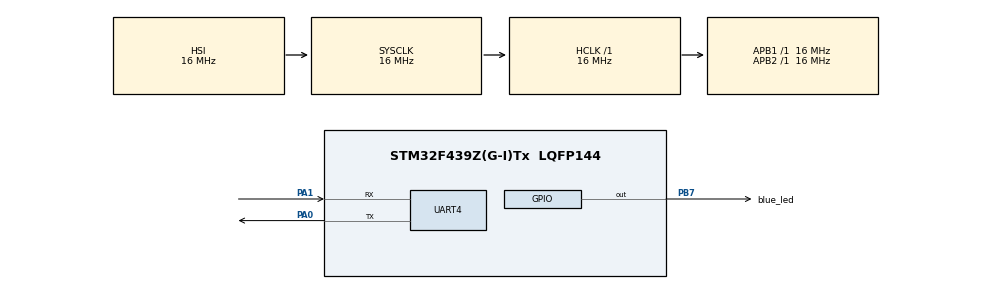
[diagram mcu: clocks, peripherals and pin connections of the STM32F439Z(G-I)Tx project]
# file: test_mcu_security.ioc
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Mcu.Family=STM32F4
Mcu.Name=STM32F439Z(G-I)Tx
Mcu.Package=LQFP144
NVIC.PriorityGroup=NVIC_PRIORITYGROUP_4
PA0/WKUP.Mode=Asynchronous
PA0/WKUP.Signal=UART4_TX
PA1.Mode=Asynchronous
PA1.Signal=UART4_RX
PB7.GPIO_Label=blue_led
PB7.Signal=GPIO_Output
ProjectManager.HeapSize=0x200
ProjectManager.StackSize=0x400
ProjectManager.TargetToolchain=STM32CubeIDE
RCC.AHBFreq_Value=16000000
RCC.APB1Freq_Value=16000000
RCC.APB2Freq_Value=16000000
RCC.CortexFreq_Value=16000000
RCC.HSE_VALUE=25000000
RCC.HSI_VALUE=16000000
RCC.LSE_VALUE=32768
RCC.SYSCLKFreq_VALUE=16000000
RCC.VCOOutputFreq_Value=192000000
UART4.VirtualMode=Asynchronous
VP_RNG_VS_RNG.Mode=RNG_Activate
VP_wolfSSL.I-CUBE-wolfSSL_VS_wolfSSLJjwolfSSL_5.5.4_5.5.4.Mode=wolfSSLJjwolfSSL
board=custom
wolfSSL.I-CUBE-wolfSSL.5.5.4.WOLF_CONF_AESGCM=0
wolfSSL.I-CUBE-wolfSSL.5.5.4.WOLF_CONF_DH=0
wolfSSL.I-CUBE-wolfSSL.5.5.4.WOLF_CONF_ECC=1
wolfSSL.I-CUBE-wolfSSL.5.5.4.WOLF_CONF_OPENSSL_EXTRA=2
wolfSSL.I-CUBE-wolfSSL.5.5.4.WOLF_CONF_TEST=0
wolfSSL.I-CUBE-wolfSSL.5.5.4.WOLF_CONF_TLS12=0
wolfSSL.I-CUBE-wolfSSL.5.5.4.wolfSSLCcwolfSSLJjwolfCryptJjCore=true
wolfSSL.I-CUBE-wolfSSL.5.5.4.wolfSSLCcwolfSSLJjwolfSSLJjCore=true

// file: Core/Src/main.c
/* USER CODE BEGIN Header */
/**
 ******************************************************************************
 * @file           : main.c
 * @brief          : Main program body
 ******************************************************************************
 * @attention
 *
 * Copyright (c) 2023 STMicroelectronics.
 * All rights reserved.
 *
 * This software is licensed under terms that can be found in the LICENSE file
 * in the root directory of this software component.
 * If no LICENSE file comes with this software, it is provided AS-IS.
 *
 ******************************************************************************
 */
/* USER CODE END Header */
#include "main.h"

/* USER CODE BEGIN Includes */
#include "stdio.h"
#include "wolfssl/wolfcrypt/signature.h"
#include "wolfssl/wolfcrypt/rsa.h"
#include "wolfssl/ssl.h"
/* USER CODE END Includes */

/* USER CODE BEGIN PM */
#define APPLICATION_EXENSIONS_ADDRESS    0x08040000

#define ROOT_CERT_ADDRESS 				 APPLICATION_EXENSIONS_ADDRESS
#define SB_CERT_ADDRESS 			    (APPLICATION_EXENSIONS_ADDRESS + 0x0800)    //0x08040800 //2K byte offset from Application_extensions_Address
#define META_DATA_ADDRESS               (APPLICATION_EXENSIONS_ADDRESS + 0x01000)   //0x08041000 //4k byte offset from Application_extensions_Address
#define SIGNATURE_ADDRESS               (APPLICATION_EXENSIONS_ADDRESS + 0x01400)	//0x08041400 //5k byte offset from Application_extensions_Address
#define CERTIFICATES_METADATA_ADDRESS   (APPLICATION_EXENSIONS_ADDRESS + 0x01600)   //0x08041600

#define MAIN_APPLICATION_START_ADDRESS  (0x08060000U)   //6k byte offset from Application_extensions_Address

#define ROOT_1_REVOCATION_ADDRESS  (0x1fff7800) //first byte in the Block 0 - OTP
#define ROOT_2_REVOCATION_ADDRESS  (0x1fff7820) //first byte in the Block 1 - OTP

#define META_DATA_LENGTH 82

#define MAJOR_V_METADATA_OFFSET         8
#define MINOR_V_METADATA_OFFSET         10
#define PATCH_V_METADATA_OFFSET         12
#define APP_SIZE__METADATA_OFFSET       20
#define ROOT_INDEX__METADATA_OFFSET     38
#define APP_HASH__METADATA_OFFSET       50

#define ROOT_CERT_SIZE_C_METADATA_OFFSET  15
#define SB_CERT_SIZE_C_METADATA_OFFSET    34
/* USER CODE END PM */

RNG_HandleTypeDef hrng;

/* USER CODE BEGIN PV */

int sigLen = 256;
byte *sigBuf =(byte *)SIGNATURE_ADDRESS;
byte *Meta_Data=(byte *)META_DATA_ADDRESS;

long expected_n_root_chain_1_public_key[] = {
		    0xa204ba2d ,0x3d6db507 ,0x4cf9130c ,0x7a2696bb ,0x3b95941b ,0x60c4c14b ,0xb9db3d47 ,
		   	0x96c5d01e ,0x4c294e55 ,0xe9fbe300 ,0x1cd028c5 ,0x8d2387e9 ,0xc1a80302 ,0x5f12af64 ,
			0x7708d0b9 ,0x9714e69d ,0xf94449d4 ,0xad00fd72 ,0xd56f1391 ,0xfb439ee5 ,0xbf35a512 ,
		   	0xda25deeb ,0xdea24a14 ,0xec3d81a2 ,0x5d44de9e ,0xfcad0f71 ,0xaabef73d ,0x63b95934 ,
		   	0xe5438b15 ,0xc92bcd84 ,0x4b7bd6b6 ,0x96080734 ,0x9e5a9a96 ,0xa30cebb2 ,0x5bf80843 ,
		   	0x69800465 ,0x135bc1db ,0x584a8dd  ,0x85a63d2c ,0x213f1976 ,0x1a5f03aa ,0xa346e215 ,
		   	0x75e22fd9 ,0x761ed052 ,0xdbeb04e3 ,0xb239e131 ,0x881d104a ,0xad471520 ,0x8aff3472 ,
		   	0x461decf  ,0xc60db6c3 ,0x775ffdc8 ,0x1281dd12 ,0x373b2262 ,0xc1c5416b ,0xa9148ac4 ,
			0xc2122bac ,0x2997d297 ,0x3ac1b66d ,0xe2796ee6 ,0xed0613e ,0x536f7034 ,0x15c594b3 ,
		   	0xb8a2cc72
};
long expected_e_root_chain_1_public_key= 0x010001;

long expected_n_root_chain_2_public_key[] = {
		0x8ca9bb9d,0xf0b5ab9a,0xe8f50ddf,0x6710305e,0xe91ab574,0x30f00f26,0xf2d6c49c,
		0x153b3795,0x2be83929,0x512688fe,0xe6e1b550,0x8cd0addf,0xe5b5fd6a,0x4e240f4c,
		0xc9504421,0xbfbcbadc,0x4ddf22de,0xee8421f2,0x53e7e1fd,0x7381cd96,0xd8e0c95 ,
		0xf607c3f ,0x35700c8e,0x50b87fc1,0x9f349d80,0x64283a4e,0x714fba4f,0x6aff8223,
		0x1871dfda,0x658d6e3f,0x422db028,0xf6c36d86,0x27179383,0x5a96bd24,0xa35533e1,
		0x221a4b4f,0xb749357 ,0xf4a5a69c,0x6e54aa51,0xe35090e2,0x8cb44963,0x29bf5a11,
		0x8b249dad,0xb3abc0a5,0x4c268acd,0xa1a5dbb4,0x55b07f26,0x5bdbfe,0xb9258160,
		0x73b75be2,0x7a4225d5,0x3a37b447,0xeb776627,0x8f337b19,0x7493a419,0x1a3a78dc,
		0x1a26114a,0xab29a71e,0xc737a1da,0xccc1b0c3,0x32ec74b4,0x58ca3b87,0xbd3f1763,
		0xe969ef22
};
long expected_e_root_chain_2_public_key= 0x010001;

/* USER CODE END PV */

void SystemClock_Config(void);
static void MX_GPIO_Init(void);
static void MX_UART4_Init(void);
static void MX_RNG_Init(void);

/* USER CODE BEGIN 0 */
int Certificates_Verify( const byte* ptr_rootCert, const byte* ptr_sbCert,int rootCert_size,int SBCert_size){
	   WOLFSSL_CERT_MANAGER* cm = NULL;
	   int ret;
	   int cSz1 = SBCert_size;
	   int cSz2 = rootCert_size;
	   wolfSSL_Init();

	   if ((cm = wolfSSL_CertManagerNew()) == NULL) {
	       printf("cert manager new failed\n");
	       return 0;
	   }

	   ret = wolfSSL_CertManagerLoadCABuffer(cm, ptr_rootCert, cSz2, SSL_FILETYPE_DEFAULT);
	   if (ret != WOLFSSL_SUCCESS) {
	       printf("loading the ca chain failed\n");
	       wolfSSL_CertManagerFree(cm);
	       return 0;
	   }

	   ret = wolfSSL_CertManagerVerifyBuffer(cm, ptr_rootCert, cSz2, SSL_FILETYPE_DEFAULT);
	   if (ret != WOLFSSL_SUCCESS) {
	       printf("could not verify certificate.\n");
	       wolfSSL_CertManagerFree(cm);
	       return 0;
	   }else{
	  	 printf("Verification successful on root cert!\n");
	   }

	   ret = wolfSSL_CertManagerVerifyBuffer(cm, ptr_sbCert, cSz1, SSL_FILETYPE_DEFAULT);
	   if (ret != WOLFSSL_SUCCESS) {
	       printf("could not verify certificate.\n");
	       wolfSSL_CertManagerFree(cm);
	       return 0;
	   }else{
	     	 printf("Verification successful on secure boot cert!\n");
	   }

	   return 0;
}

int signature_verify(const byte* signature, int sig_length, const byte* metaData,int metadata_lengt, RsaKey *pubKey){

	Sha256         sha256;
	Sha256*        pSha256 = NULL;

	unsigned char  digest[WC_SHA256_DIGEST_SIZE];
	unsigned char  encSig[WC_SHA256_DIGEST_SIZE + 32];
	word32         encSigLen = 0;
	unsigned char* decSig = NULL;
	word32         decSigLen = 0;
	int ret=0;

	/* Calculate SHA-256 digest of message */
	if (ret == 0){
		ret = wc_InitSha256(&sha256);
	}
	if (ret == 0) {
		pSha256 = &sha256;
		ret = wc_Sha256Update(&sha256, metaData, metadata_lengt);   //size of() should be implemented but maybe -1, dep on the format of the meta data (array of hex or string)
	}
	if (ret == 0){
		ret = wc_Sha256Final(&sha256, digest);
	}

	/** using the hash function **/

	//digest = wc_CalculateDigest(metaData,34);

	/* Encode digest with algorithm information as per PKCS#1.5 */
	if (ret == 0) {
		encSigLen = wc_EncodeSignature(encSig, digest, sizeof(digest), SHA256h);
		if ((int)encSigLen < 0){
			ret = (int)encSigLen;
		}
	}

	/* Verify the signature by decrypting the value */
	if (ret == 0) {
		decSigLen = wc_RsaSSL_VerifyInline(signature, sig_length, &decSig, pubKey);
		if ((int)decSigLen < 0){
			ret = (int)decSigLen;
		}
	}

	/* Check the decrypted result matches the encoded digest. */
	if (ret == 0 && encSigLen != decSigLen){
		/* failure */
		ret = -1;
	}

	if (ret == 0 && XMEMCMP(encSig, decSig, encSigLen) != 0){
		/* failure */
		ret = -1;
	}

	/*free*/
	if (pSha256 != NULL){
		wc_Sha256Free(pSha256);
	}

	/* Report on the verification */
	return ret;

}

byte * CalculateDigest(const byte* image , int image_size )
{
	/*
	 * Variables Declaration
	 */
	  wc_Sha256 sha256;
	 static byte hash[WC_SHA256_DIGEST_SIZE];  //Hash value

	  int ret = -1;

	  //Initialization of SHA256
	  ret = wc_InitSha256(&sha256);
	  if (ret != 0)
	  {
		  printf("Failed to initialize SHA structure\n");
	  }

	  //calculate digest API
	  ret = wc_Sha256Update(&sha256, image , image_size);
	  if (ret != 0)
	  {
	       printf("Failed to calculate the hash\n");
	  }

	  else if (ret == 0)
	  {
		  ret =  wc_Sha256Final(&sha256, hash);

	  }
	  if (ret != 0)
	  {
	       printf("ERROR: Hash operation failed");
	  }

	  else
	  {
		/*
		 * Do nothing
		 */
	  }
	  return hash;
}

int DigestCompare ( byte *Digest , byte *MetaDigest)
{
       int ret = 0;
      ret = memcmp(Digest,MetaDigest,32);
      return ret;
}

int public_key_Extraction(const byte* ptr_Cert,int Cert_size,RsaKey *pubKey){

	int ret =0;
	WOLFSSL_X509* x509cert;
	WOLFSSL_EVP_PKEY* pubKeyTmp;
	word32 idx = 0;

	x509cert = wolfSSL_X509_load_certificate_buffer(ptr_Cert, Cert_size, WOLFSSL_FILETYPE_DEFAULT);
	if (x509cert == NULL) {
		printf("Failed to load cert, abort!\n");
		return ret;
	}
	printf("Loaded cert successfully\n");

	pubKeyTmp = wolfSSL_X509_get_pubkey(x509cert);
	if (pubKeyTmp == NULL) {
		printf("Failed to extract public key, abort!\n");
		return ret;
	}
	printf("Extracted public key successfully\n");

	/* setup a key structure to receive the extracted key */
	wc_InitRsaKey(pubKey, NULL);
	ret = wc_RsaPublicKeyDecode((byte*)pubKeyTmp->pkey.ptr, &idx, pubKey,
			(word32) pubKeyTmp->pkey_sz);
	if (ret != 0) {
		printf("Failed to decode public key from pubKeyTmp, abort!\n");
		return ret;
	}
	printf("Successfully decoded public key\n");
	wolfSSL_EVP_PKEY_free(pubKeyTmp);
	wolfSSL_X509_free(x509cert);
	ret =0;
	return ret;
}

int compare_long(long *n_public_key_1,long *n_public_key_2,int size){

	for(int i=0;i<size;i++){
		if(n_public_key_1[i] != n_public_key_2[i]){
			return 1;
		}
	}
	return 0;
}

int Secure_boot_goooooo(){
	int ret=0;
	/************** fetch needed data from memory****************/
	byte rootIndex = *((char *)META_DATA_ADDRESS+ROOT_INDEX__METADATA_OFFSET) - '0';
	int appSize = atoi((char *)META_DATA_ADDRESS+APP_SIZE__METADATA_OFFSET);

	  const byte* ptr_sbCert = (byte*)(SB_CERT_ADDRESS);
	  const byte* ptr_rootCert = (byte*)(ROOT_CERT_ADDRESS);

	  int SB_cert_size = atoi((char *)CERTIFICATES_METADATA_ADDRESS + SB_CERT_SIZE_C_METADATA_OFFSET);
	  int root_cert_size = atoi((char *)CERTIFICATES_METADATA_ADDRESS +ROOT_CERT_SIZE_C_METADATA_OFFSET);

	/*************** Root certificates Revocation*********************/
	 byte root_1_revoked = *((byte *)ROOT_1_REVOCATION_ADDRESS);
	 byte root_2_revoked = *((byte *)ROOT_2_REVOCATION_ADDRESS);
	  if(((rootIndex == 1) && (root_1_revoked != 0xff)) || ((rootIndex == 2) && (root_2_revoked != 0xff))){
		  return 1;
	  }

	  /*************** certificates verifications *********************/
	  ret = Certificates_Verify(ptr_rootCert, ptr_sbCert, root_cert_size, SB_cert_size);
	   if (ret != 0){
		   return 1;
	   }
	   /*****************************************************/
	   /************* Check Anchor  ************************/
	   /*****************************************************/

	   RsaKey ROOT_pubKey ;
	   ret = public_key_Extraction(ptr_rootCert,root_cert_size,&ROOT_pubKey);
	   if (ret != 0){
		   return 1;
	   }

	   //based on root index
	   if(rootIndex == 1){
		    /*********** compare n value *************/
			ret = compare_long((long *)expected_n_root_chain_1_public_key,(long *)ROOT_pubKey.n.dp,64);
		    if (ret != 0){
				   return 1;
		    }
			/*********** compare e value   ***********/
			ret = !((long)(ROOT_pubKey.e.dp[0]) == expected_e_root_chain_1_public_key);
			if (ret != 0){
			   return 1;
			}
	   }else if(rootIndex == 2){
		   /*********** compare n value *************/
			ret = compare_long((long *)expected_n_root_chain_2_public_key,(long *)ROOT_pubKey.n.dp,64);
			if (ret != 0){
				   return 1;
			}
			/*********** compare e value   ***********/
			ret = !((long)(ROOT_pubKey.e.dp[0]) == expected_e_root_chain_2_public_key);
			if (ret != 0){
			   return 1;
			}
	   }else{
		   return 1;
	   }

	  /************** secure boot public key Extraction ****************/
	   RsaKey SB_pubKey ;
	   ret = public_key_Extraction(ptr_sbCert,SB_cert_size,&SB_pubKey);
	   if (ret != 0){
		   return 1;
	   }

	   /******* signature verification ********/
		byte sigBuffer [256];
		uint32_t StartSectorAddress = SIGNATURE_ADDRESS;
		for(int i=0;i<256;i++){
			sigBuffer [i]= *(uint8_t *)StartSectorAddress;
			StartSectorAddress++;
		}
		ret=signature_verify(sigBuffer,sigLen, Meta_Data,META_DATA_LENGTH ,&SB_pubKey);
		if (ret == 0){
			printf("Verified\n");
		}
		else{
			printf("Failure\n");
		}
		wc_FreeRsaKey(&SB_pubKey);

		/************* Threshold  *****************/

		byte Major_Version = *((char *)META_DATA_ADDRESS+MAJOR_V_METADATA_OFFSET) - '0';
		byte Minor_Version = *((char *)META_DATA_ADDRESS+MINOR_V_METADATA_OFFSET) - '0';
		byte Patch_Version = *((char *)META_DATA_ADDRESS+PATCH_V_METADATA_OFFSET) - '0';

//		int Threshold = *((byte*)0x080E000C);
//		int Current_Version = *(rawData+8);
//		if (Current_Version < Threshold ){
//			return 1;
//		}

		/************* Hash  ***************/
		byte *Hash_value= (byte*)(Meta_Data+APP_HASH__METADATA_OFFSET);
		byte *Start_Add_App = (byte*)MAIN_APPLICATION_START_ADDRESS;
		byte *Hash_Result = CalculateDigest( Start_Add_App ,appSize );
		ret = DigestCompare ( Hash_Result , Hash_value);
		if(ret!=0){
			return 1;
		}
		printf("Succeed\n");

	   	return ret;
}
/* USER CODE END 0 */

int main(void)
{

  /* MCU Configuration--------------------------------------------------------*/

  /* Reset of all peripherals, Initializes the Flash interface and the Systick. */
  HAL_Init();

  /* Configure the system clock */
  SystemClock_Config();

  /* Initialize all configured peripherals */
  MX_GPIO_Init();
  MX_UART4_Init();
  MX_RNG_Init();

  /* Infinite loop */
  /* USER CODE BEGIN WHILE */
  bootloader_jump_to_application(0x08060000);
	while (1)
	{
		//HAL_GPIO_TogglePin(blue_led_GPIO_Port, blue_led_Pin);
		//HAL_Delay(1000);
    /* USER CODE END WHILE */

	}
}

void SystemClock_Config(void)
{
  RCC_OscInitTypeDef RCC_OscInitStruct = {0};
  RCC_ClkInitTypeDef RCC_ClkInitStruct = {0};

  /** Configure the main internal regulator output voltage
  */
  __HAL_RCC_PWR_CLK_ENABLE();
  __HAL_PWR_VOLTAGESCALING_CONFIG(PWR_REGULATOR_VOLTAGE_SCALE3);

  /** Initializes the RCC Oscillators according to the specified parameters
  * in the RCC_OscInitTypeDef structure.
  */
  RCC_OscInitStruct.OscillatorType = RCC_OSCILLATORTYPE_HSI;
  RCC_OscInitStruct.HSIState = RCC_HSI_ON;
  RCC_OscInitStruct.HSICalibrationValue = RCC_HSICALIBRATION_DEFAULT;
  RCC_OscInitStruct.PLL.PLLState = RCC_PLL_ON;
  RCC_OscInitStruct.PLL.PLLSource = RCC_PLLSOURCE_HSI;
  RCC_OscInitStruct.PLL.PLLM = 16;
  RCC_OscInitStruct.PLL.PLLN = 192;
  RCC_OscInitStruct.PLL.PLLP = RCC_PLLP_DIV2;
  RCC_OscInitStruct.PLL.PLLQ = 4;
  if (HAL_RCC_OscConfig(&RCC_OscInitStruct) != HAL_OK)
  {
    Error_Handler();
  }

  /** Initializes the CPU, AHB and APB buses clocks
  */
  RCC_ClkInitStruct.ClockType = RCC_CLOCKTYPE_HCLK|RCC_CLOCKTYPE_SYSCLK
                              |RCC_CLOCKTYPE_PCLK1|RCC_CLOCKTYPE_PCLK2;
  RCC_ClkInitStruct.SYSCLKSource = RCC_SYSCLKSOURCE_HSI;
  RCC_ClkInitStruct.AHBCLKDivider = RCC_SYSCLK_DIV1;
  RCC_ClkInitStruct.APB1CLKDivider = RCC_HCLK_DIV1;
  RCC_ClkInitStruct.APB2CLKDivider = RCC_HCLK_DIV1;

  if (HAL_RCC_ClockConfig(&RCC_ClkInitStruct, FLASH_LATENCY_0) != HAL_OK)
  {
    Error_Handler();
  }
}

static void MX_RNG_Init(void)
{

  hrng.Instance = RNG;
  if (HAL_RNG_Init(&hrng) != HAL_OK)
  {
    Error_Handler();
  }

}

static void MX_UART4_Init(void)
{

  LL_USART_InitTypeDef USART_InitStruct = {0};

  LL_GPIO_InitTypeDef GPIO_InitStruct = {0};

  /* Peripheral clock enable */
  LL_APB1_GRP1_EnableClock(LL_APB1_GRP1_PERIPH_UART4);

  LL_AHB1_GRP1_EnableClock(LL_AHB1_GRP1_PERIPH_GPIOA);
  /**UART4 GPIO Configuration
  PA0/WKUP   ------> UART4_TX
  PA1   ------> UART4_RX
  */
  GPIO_InitStruct.Pin = LL_GPIO_PIN_0|LL_GPIO_PIN_1;
  GPIO_InitStruct.Mode = LL_GPIO_MODE_ALTERNATE;
  GPIO_InitStruct.Speed = LL_GPIO_SPEED_FREQ_VERY_HIGH;
  GPIO_InitStruct.OutputType = LL_GPIO_OUTPUT_PUSHPULL;
  GPIO_InitStruct.Pull = LL_GPIO_PULL_NO;
  GPIO_InitStruct.Alternate = LL_GPIO_AF_8;
  LL_GPIO_Init(GPIOA, &GPIO_InitStruct);

  USART_InitStruct.BaudRate = 115200;
  USART_InitStruct.DataWidth = LL_USART_DATAWIDTH_8B;
  USART_InitStruct.StopBits = LL_USART_STOPBITS_1;
  USART_InitStruct.Parity = LL_USART_PARITY_NONE;
  USART_InitStruct.TransferDirection = LL_USART_DIRECTION_TX_RX;
  USART_InitStruct.HardwareFlowControl = LL_USART_HWCONTROL_NONE;
  USART_InitStruct.OverSampling = LL_USART_OVERSAMPLING_16;
  LL_USART_Init(UART4, &USART_InitStruct);
  LL_USART_ConfigAsyncMode(UART4);
  LL_USART_Enable(UART4);

}

static void MX_GPIO_Init(void)
{
  GPIO_InitTypeDef GPIO_InitStruct = {0};

  /* GPIO Ports Clock Enable */
  __HAL_RCC_GPIOA_CLK_ENABLE();
  __HAL_RCC_GPIOB_CLK_ENABLE();

  /*Configure GPIO pin Output Level */
  HAL_GPIO_WritePin(blue_led_GPIO_Port, blue_led_Pin, GPIO_PIN_RESET);

  /*Configure GPIO pin : blue_led_Pin */
  GPIO_InitStruct.Pin = blue_led_Pin;
  GPIO_InitStruct.Mode = GPIO_MODE_OUTPUT_PP;
  GPIO_InitStruct.Pull = GPIO_NOPULL;
  GPIO_InitStruct.Speed = GPIO_SPEED_FREQ_LOW;
  HAL_GPIO_Init(blue_led_GPIO_Port, &GPIO_InitStruct);

}

void Error_Handler(void)
{
	__disable_irq();
	while (1)
	{
	}
}
